# R7FA2A2AD register map
Vendor: Renesas Electronics Corporation; Series: RA2A2; File version: 1.20.02
CPU: CM23 r1p0, little endian, MPU, no FPU, VTOR, 2 interrupt priority bits, 32 interrupts
Registers are 8-bit, read-write, reset 0x0 unless marked. A register's access mark holds for its fields unless they carry their own. Offsets are from the block's base; [hi:lo] are bit positions; {n}, {i} and the like mark numbered series; 'fields as' and 'values as' point back to an identical list.

## ELC — Event Link Controller
Base 0x40041000
0x00 ELCR — Event Link Controller Register
  [7] ELCON — All Event Link Enable
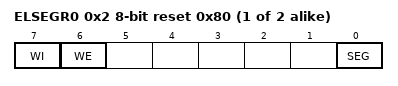
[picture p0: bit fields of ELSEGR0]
{0x2+2i} ELSEGR{i} (i=0..1) reset 0x80 — Event Link Software Event Generation Register {i}
  [7] WI wo — ELSEGR Register Write Disable
  [6] WE — SEG Bit Write Enable
  [0] SEG wo — Software Event Generation
{0x10+4i} ELSR{i} (i=0..3) 16-bit — Event Link Setting Register {i}
  [7:0] ELS — Event Link Select
{0x10+4i} ELSR{i}_1 (i=8..9) 16-bit — Event Link Setting Register {i}
  [7:0] ELS — Event Link Select
{0x10+4i} ELSR{i}_2 (i=14..15) 16-bit — Event Link Setting Register {i}
  [7:0] ELS — Event Link Select

## POEG — Port Output Enable Module for GPT
Base 0x40042000
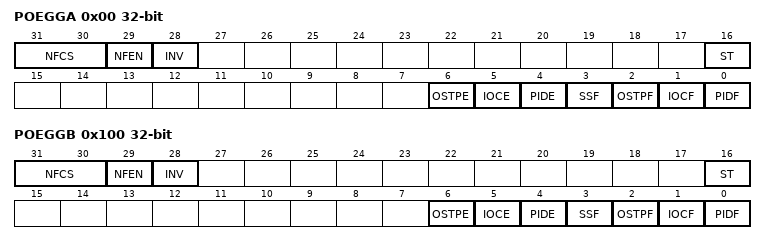
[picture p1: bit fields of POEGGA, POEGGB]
0x00 POEGGA 32-bit — POEG Group A Setting Register
  [31:30] NFCS — Noise Filter Clock Select
  [29] NFEN — Noise Filter Enable
  [28] INV — GTETRGn Input Reverse
  [16] ST ro — GTETRGn Input Status Flag
  [6] OSTPE — Oscillation Stop Detection Enable
  [5] IOCE — Enable for GPT Output,Disable Request
  [4] PIDE — Port Input Detection Enable
  [3] SSF — Software Stop Flag
  [2] OSTPF — Oscillation Stop Detection Flag
  [1] IOCF — Detection Flag for GPT Output,Disable Request
  [0] PIDF — Port Input Detection Flag
0x100 POEGGB 32-bit — POEG Group B Setting Register
  fields as POEGGA

## WDT — Watchdog Timer
Base 0x40044200
0x00 WDTRR reset 0xFF — WDT Refresh Register
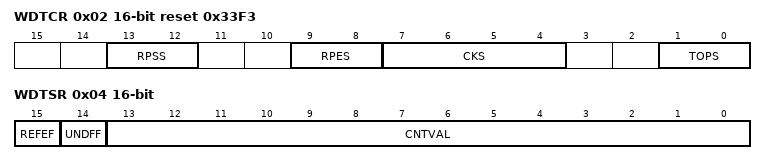
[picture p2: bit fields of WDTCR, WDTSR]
0x02 WDTCR 16-bit reset 0x33F3 — WDT Control Register
  [13:12] RPSS — Window Start Position Select
  [9:8] RPES — Window End Position Select
  [7:4] CKS — Clock Division Ratio Select
  [1:0] TOPS — Timeout Period Select
0x04 WDTSR 16-bit — WDT Status Register
  [15] REFEF — Refresh Error Flag
  [14] UNDFF — Underflow Flag
  [13:0] CNTVAL ro — Down,Counter Value
0x06 WDTRCR reset 0x80 — WDT Reset Control Register
  [7] RSTIRQS — WDT Behavior Selection
0x08 WDTCSTPR reset 0x80 — WDT Count Stop Control Register
  [7] SLCSTP — Sleep,Mode Count Stop Control Register

## IWDT — Independent Watchdog Timer
Base 0x40044400
0x00 IWDTRR reset 0xFF — IWDT Refresh Register
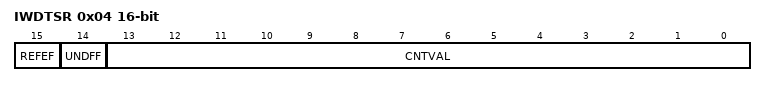
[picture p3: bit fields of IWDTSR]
0x04 IWDTSR 16-bit — IWDT Status Register
  [15] REFEF — Refresh Error Flag
  [14] UNDFF — Underflow Flag
  [13:0] CNTVAL ro — Down,counter Value

## CAC — Clock Frequency Accuracy Measurement Circuit
Base 0x40044600
0x00 CACR0 — CAC Control Register 0
  [0] CFME — Clock Frequency Measurement Enable
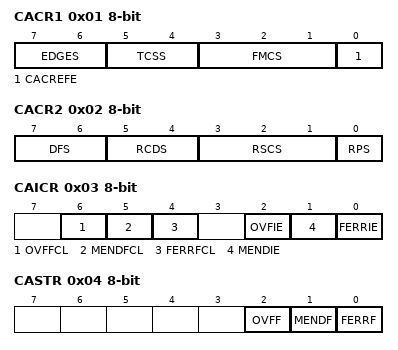
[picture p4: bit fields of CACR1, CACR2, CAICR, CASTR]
0x01 CACR1 — CAC Control Register 1
  [7:6] EDGES — Valid Edge Select
  [5:4] TCSS — Timer Count Clock Source Select
  [3:1] FMCS — Measurement Target Clock Select
  [0] CACREFE — CACREF Pin Input Enable
0x02 CACR2 — CAC Control Register 2
  [7:6] DFS — Digital Filter Select
  [5:4] RCDS — Measurement Reference Clock Frequency Division Ratio Select
  [3:1] RSCS — Measurement Reference Clock Select
  [0] RPS — Reference Signal Select
0x03 CAICR — CAC Interrupt Control Register
  [6] OVFFCL wo — OVFF Clear
  [5] MENDFCL wo — MENDF Clear
  [4] FERRFCL wo — FERRF Clear
  [2] OVFIE — Overflow Interrupt Request Enable
  [1] MENDIE — Measurement End Interrupt Request Enable
  [0] FERRIE — Frequency Error Interrupt Request Enable
0x04 CASTR ro — CAC Status Register
  [2] OVFF — Overflow Flag
  [1] MENDF — Measurement End Flag
  [0] FERRF — Frequency Error Flag
0x06 CAULVR 16-bit — CAC Upper,Limit Value Setting Register
0x08 CALLVR 16-bit — CAC Lower,Limit Value Setting Register
0x0A CACNTBR 16-bit ro — CAC Counter Buffer Register

## MSTP — Module Stop Control A, B, C, D
Base 0x40047000
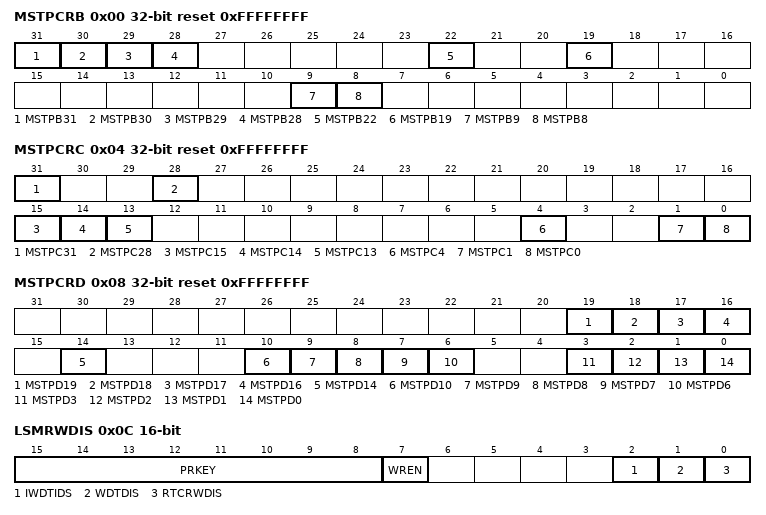
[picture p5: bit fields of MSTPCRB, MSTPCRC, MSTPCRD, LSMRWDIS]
0x00 MSTPCRB 32-bit reset 0xFFFFFFFF — Module Stop Control Register B
  [31] MSTPB31 — Serial Communication Interface 0 Module Stop
  [30] MSTPB30 — Serial Communication Interface 1 Module Stop
  [29] MSTPB29 — Serial Communication Interface 2 Module Stop
  [28] MSTPB28 — Serial Communication Interface 3 Module Stop
  [22] MSTPB22 — Serial Communication Interface 9 Module Stop
  [19] MSTPB19 — Serial Peripheral Interface 0 Module Stop
  [9] MSTPB9 — I2C Bus Interface 0 Module Stop
  [8] MSTPB8 — I2C Bus Interface 1 Module Stop
0x04 MSTPCRC 32-bit reset 0xFFFFFFFF — Module Stop Control Register C
  [31] MSTPC31 — AES Module Stop
  [28] MSTPC28 — True Random Number Generator Module Stop
  [15] MSTPC15 — 32-bit Multiply,Accumulator Module Stop
  [14] MSTPC14 — Event Link Controller Module Stop
  [13] MSTPC13 — Data Operation Circuit Module Stop
  [4] MSTPC4 — Segment LCD Controller Module Stop
  [1] MSTPC1 — Cyclic Redundancy Check Calculator Module Stop
  [0] MSTPC0 — Clock Frequency Accuracy Measurement Circuit Module Stop
0x08 MSTPCRD 32-bit reset 0xFFFFFFFF — Module Stop Control Register D
  [19] MSTPD19 — 16-bit Low Power Asynchronous General Purpose Timer 0 Module Stop
  [18] MSTPD18 — 16-bit Low Power Asynchronous General Purpose Timer 1 Module Stop
  [17] MSTPD17 — 24-bit Sigma,Delta A/D Converter Module Stop
  [16] MSTPD16 — 12-bit A/D Converter Module Stop
  [14] MSTPD14 — Port Output Enable for GPT Module Stop
  [10] MSTPD10 — 16-bit Low Power Asynchronous General Purpose Timer 4 Module Stop
  [9] MSTPD9 — 16-bit Low Power Asynchronous General Purpose Timer 5 Module Stop
  [8] MSTPD8 — 16-bit Low Power Asynchronous General Purpose Timer 6 Module Stop
  [7] MSTPD7 — 16-bit Low Power Asynchronous General Purpose Timer 7 Module Stop
  [6] MSTPD6 — General PWM Timer 164 to 169 and PWM Delay Generation Circuit Module Stop
  [3] MSTPD3 — 32-bit Low Power Asynchronous General Purpose Timer 0 Module Stop
  [2] MSTPD2 — 32-bit Low Power Asynchronous General Purpose Timer 1 Module Stop
  [1] MSTPD1 — 16-bit Low Power Asynchronous General Purpose Timer 2 Module Stop
  [0] MSTPD0 — 16-bit Low Power Asynchronous General Purpose Timer 3 Module Stop
0x0C LSMRWDIS 16-bit — Low Speed Module R/W Disable Control Register
  [15:8] PRKEY wo — LSMRWDIS Key Code
  [7] WREN — Write Enable for bits [2:0]
  [2] IWDTIDS — IWDT Register Clock Control
  [1] WDTDIS — WDT Operate Clock Control
  [0] RTCRWDIS — RTC Register R/W Enable Control
